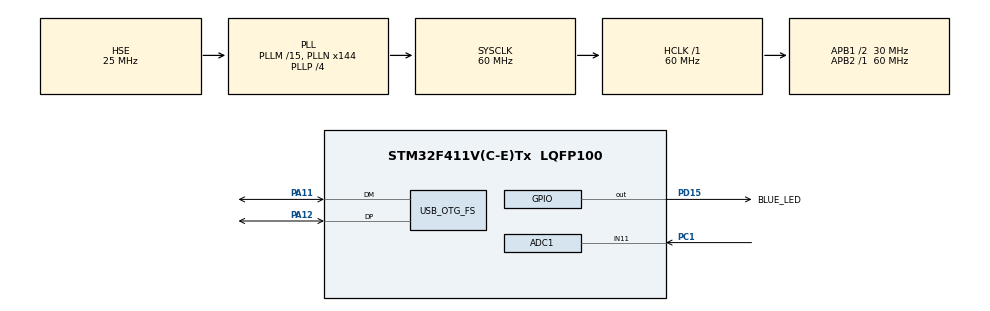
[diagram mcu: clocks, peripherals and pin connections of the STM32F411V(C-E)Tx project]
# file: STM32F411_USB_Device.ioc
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Mcu.Family=STM32F4
USB_DEVICE.CLASS_NAME_FS=CDC
Dma.ADC1.0.Instance=DMA2_Stream0
RCC.CortexFreq_Value=60000000
ADC1.Rank-0\#ChannelRegularConversion=1
PD15.GPIO_Label=BLUE_LED
ADC1.ContinuousConvMode=ENABLE
USB_DEVICE.VirtualModeFS=Cdc_FS
PH1\ -\ OSC_OUT.Mode=HSE-External-Oscillator
PA11.Mode=Device_Only
RCC.APB1CLKDivider=RCC_HCLK_DIV2
RCC.SYSCLKSource=RCC_SYSCLKSOURCE_PLLCLK
ProjectManager.StackSize=0x400
PA13.Signal=SYS_JTMS-SWDIO
Dma.ADC1.0.PeriphDataAlignment=DMA_PDATAALIGN_WORD
PA12.Signal=USB_OTG_FS_DP
PH0\ -\ OSC_IN.Mode=HSE-External-Oscillator
PH0\ -\ OSC_IN.Signal=RCC_OSC_IN
ProjectManager.TargetToolchain=STM32CubeIDE
USB_DEVICE.PRODUCT_STRING_CDC_FS=DiscoF411_VComPort
Dma.ADC1.0.Mode=DMA_CIRCULAR
RCC.HCLKFreq_Value=60000000
VP_USB_DEVICE_VS_USB_DEVICE_CDC_FS.Mode=CDC_FS
Dma.ADC1.0.Priority=DMA_PRIORITY_LOW
RCC.APB2TimFreq_Value=60000000
Dma.ADC1.0.Direction=DMA_PERIPH_TO_MEMORY
NVIC.DMA2_Stream0_IRQn=true\:0\:0\:false\:false\:true\:false\:true
RCC.LSE_VALUE=32768
Dma.ADC1.0.MemDataAlignment=DMA_MDATAALIGN_WORD
RCC.AHBFreq_Value=60000000
ADC1.Channel-0\#ChannelRegularConversion=ADC_CHANNEL_11
RCC.HSE_VALUE=25000000
PH1\ -\ OSC_OUT.Signal=RCC_OSC_OUT
ADC1.ScanConvMode=DISABLE
board=custom
RCC.VCOOutputFreq_Value=240000000
RCC.APB2Freq_Value=60000000
SH.ADCx_IN11.0=ADC1_IN11,IN11
PA14.Mode=Serial_Wire
Dma.ADC1.0.PeriphInc=DMA_PINC_DISABLE
PA13.Mode=Serial_Wire
Mcu.Name=STM32F411V(C-E)Tx
ADC1.SamplingTime-0\#ChannelRegularConversion=ADC_SAMPLETIME_28CYCLES
RCC.48MHZClocksFreq_Value=48000000
RCC.SYSCLKFreq_VALUE=60000000
Mcu.Package=LQFP100
ADC1.master=1
PA12.Mode=Device_Only
NVIC.OTG_FS_IRQn=true\:0\:0\:false\:false\:true\:false\:true
PA11.Signal=USB_OTG_FS_DM
PA14.Signal=SYS_JTCK-SWCLK
Dma.ADC1.0.MemInc=DMA_MINC_ENABLE
USB_OTG_FS.VirtualMode=Device_Only
ProjectManager.HeapSize=0x200
RCC.HSI_VALUE=16000000
RCC.PLLP=RCC_PLLP_DIV4
RCC.PLLQ=5
NVIC.PriorityGroup=NVIC_PRIORITYGROUP_4
ADC1.NbrOfConversionFlag=1
RCC.PLLM=15
RCC.PLLN=144
RCC.APB1TimFreq_Value=60000000
Dma.ADC1.0.FIFOMode=DMA_FIFOMODE_DISABLE
Dma.Request0=ADC1
RCC.APB1Freq_Value=30000000
USB_DEVICE.VirtualMode=Cdc
ADC1.ClockPrescaler=ADC_CLOCK_SYNC_PCLK_DIV8
PD15.Signal=GPIO_Output
PC1.Signal=ADCx_IN11

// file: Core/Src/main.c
/* USER CODE BEGIN Header */
/**
  ******************************************************************************
  * @file           : main.c
  * @brief          : Main program body
  ******************************************************************************
  * @attention
  *
  * <h2><center>&copy; Copyright (c) 2021 STMicroelectronics.
  * All rights reserved.</center></h2>
  *
  * This software component is licensed by ST under BSD 3-Clause license,
  * the "License"; You may not use this file except in compliance with the
  * License. You may obtain a copy of the License at:
  *                        opensource.org/licenses/BSD-3-Clause
  *
  ******************************************************************************
  */
/* USER CODE END Header */
#include "main.h"
#include "usb_device.h"
#include <stdio.h>
#include <string.h>
/* USER CODE BEGIN Includes */
#include "usbd_cdc_if.h"

/* USER CODE END Includes */

ADC_HandleTypeDef hadc1;
DMA_HandleTypeDef hdma_adc1;

/* USER CODE BEGIN PV */
uint32_t ADC_VAL;
char *data[15];
/* USER CODE END PV */

void SystemClock_Config(void);
static void MX_GPIO_Init(void);
static void MX_DMA_Init(void);
static void MX_ADC1_Init(void);

int main(void)
{

  /* MCU Configuration--------------------------------------------------------*/

  /* Reset of all peripherals, Initializes the Flash interface and the Systick. */
  HAL_Init();

  /* Configure the system clock */
  SystemClock_Config();

  /* Initialize all configured peripherals */
  MX_GPIO_Init();
  MX_DMA_Init();
  MX_ADC1_Init();
  MX_USB_DEVICE_Init();
  /* USER CODE BEGIN 2 */
  HAL_ADC_Start_DMA(&hadc1, &ADC_VAL, sizeof(ADC_VAL));
  /* USER CODE END 2 */

  /* Infinite loop */
  while (1)
  {

    /* USER CODE BEGIN 3 */
	  sprintf(*data, "ADC Value is %4ld \n",ADC_VAL);
	  CDC_Transmit_FS((uint8_t*)data, strlen(*data));
	  HAL_Delay(100);
  }
  /* USER CODE END 3 */
}

void SystemClock_Config(void)
{
  RCC_OscInitTypeDef RCC_OscInitStruct = {0};
  RCC_ClkInitTypeDef RCC_ClkInitStruct = {0};

  /** Configure the main internal regulator output voltage
  */
  __HAL_RCC_PWR_CLK_ENABLE();
  __HAL_PWR_VOLTAGESCALING_CONFIG(PWR_REGULATOR_VOLTAGE_SCALE1);
  /** Initializes the RCC Oscillators according to the specified parameters
  * in the RCC_OscInitTypeDef structure.
  */
  RCC_OscInitStruct.OscillatorType = RCC_OSCILLATORTYPE_HSE;
  RCC_OscInitStruct.HSEState = RCC_HSE_ON;
  RCC_OscInitStruct.PLL.PLLState = RCC_PLL_ON;
  RCC_OscInitStruct.PLL.PLLSource = RCC_PLLSOURCE_HSE;
  RCC_OscInitStruct.PLL.PLLM = 15;
  RCC_OscInitStruct.PLL.PLLN = 144;
  RCC_OscInitStruct.PLL.PLLP = RCC_PLLP_DIV4;
  RCC_OscInitStruct.PLL.PLLQ = 5;
  if (HAL_RCC_OscConfig(&RCC_OscInitStruct) != HAL_OK)
  {
    Error_Handler();
  }
  /** Initializes the CPU, AHB and APB buses clocks
  */
  RCC_ClkInitStruct.ClockType = RCC_CLOCKTYPE_HCLK|RCC_CLOCKTYPE_SYSCLK
                              |RCC_CLOCKTYPE_PCLK1|RCC_CLOCKTYPE_PCLK2;
  RCC_ClkInitStruct.SYSCLKSource = RCC_SYSCLKSOURCE_PLLCLK;
  RCC_ClkInitStruct.AHBCLKDivider = RCC_SYSCLK_DIV1;
  RCC_ClkInitStruct.APB1CLKDivider = RCC_HCLK_DIV2;
  RCC_ClkInitStruct.APB2CLKDivider = RCC_HCLK_DIV1;

  if (HAL_RCC_ClockConfig(&RCC_ClkInitStruct, FLASH_LATENCY_1) != HAL_OK)
  {
    Error_Handler();
  }
}

static void MX_ADC1_Init(void)
{

  ADC_ChannelConfTypeDef sConfig = {0};

  /** Configure the global features of the ADC (Clock, Resolution, Data Alignment and number of conversion)
  */
  hadc1.Instance = ADC1;
  hadc1.Init.ClockPrescaler = ADC_CLOCK_SYNC_PCLK_DIV8;
  hadc1.Init.Resolution = ADC_RESOLUTION_12B;
  hadc1.Init.ScanConvMode = DISABLE;
  hadc1.Init.ContinuousConvMode = ENABLE;
  hadc1.Init.DiscontinuousConvMode = DISABLE;
  hadc1.Init.ExternalTrigConvEdge = ADC_EXTERNALTRIGCONVEDGE_NONE;
  hadc1.Init.ExternalTrigConv = ADC_SOFTWARE_START;
  hadc1.Init.DataAlign = ADC_DATAALIGN_RIGHT;
  hadc1.Init.NbrOfConversion = 1;
  hadc1.Init.DMAContinuousRequests = DISABLE;
  hadc1.Init.EOCSelection = ADC_EOC_SINGLE_CONV;
  if (HAL_ADC_Init(&hadc1) != HAL_OK)
  {
    Error_Handler();
  }
  /** Configure for the selected ADC regular channel its corresponding rank in the sequencer and its sample time.
  */
  sConfig.Channel = ADC_CHANNEL_11;
  sConfig.Rank = 1;
  sConfig.SamplingTime = ADC_SAMPLETIME_28CYCLES;
  if (HAL_ADC_ConfigChannel(&hadc1, &sConfig) != HAL_OK)
  {
    Error_Handler();
  }

}

static void MX_DMA_Init(void)
{

  /* DMA controller clock enable */
  __HAL_RCC_DMA2_CLK_ENABLE();

  /* DMA interrupt init */
  /* DMA2_Stream0_IRQn interrupt configuration */
  HAL_NVIC_SetPriority(DMA2_Stream0_IRQn, 0, 0);
  HAL_NVIC_EnableIRQ(DMA2_Stream0_IRQn);

}

static void MX_GPIO_Init(void)
{
  GPIO_InitTypeDef GPIO_InitStruct = {0};

  /* GPIO Ports Clock Enable */
  __HAL_RCC_GPIOH_CLK_ENABLE();
  __HAL_RCC_GPIOC_CLK_ENABLE();
  __HAL_RCC_GPIOD_CLK_ENABLE();
  __HAL_RCC_GPIOA_CLK_ENABLE();

  /*Configure GPIO pin Output Level */
  HAL_GPIO_WritePin(BLUE_LED_GPIO_Port, BLUE_LED_Pin, GPIO_PIN_RESET);

  /*Configure GPIO pin : BLUE_LED_Pin */
  GPIO_InitStruct.Pin = BLUE_LED_Pin;
  GPIO_InitStruct.Mode = GPIO_MODE_OUTPUT_PP;
  GPIO_InitStruct.Pull = GPIO_NOPULL;
  GPIO_InitStruct.Speed = GPIO_SPEED_FREQ_LOW;
  HAL_GPIO_Init(BLUE_LED_GPIO_Port, &GPIO_InitStruct);

}

void Error_Handler(void)
{
  __disable_irq();
  while (1)
  {
  }
}

/************************ (C) COPYRIGHT STMicroelectronics *****END OF FILE****/
